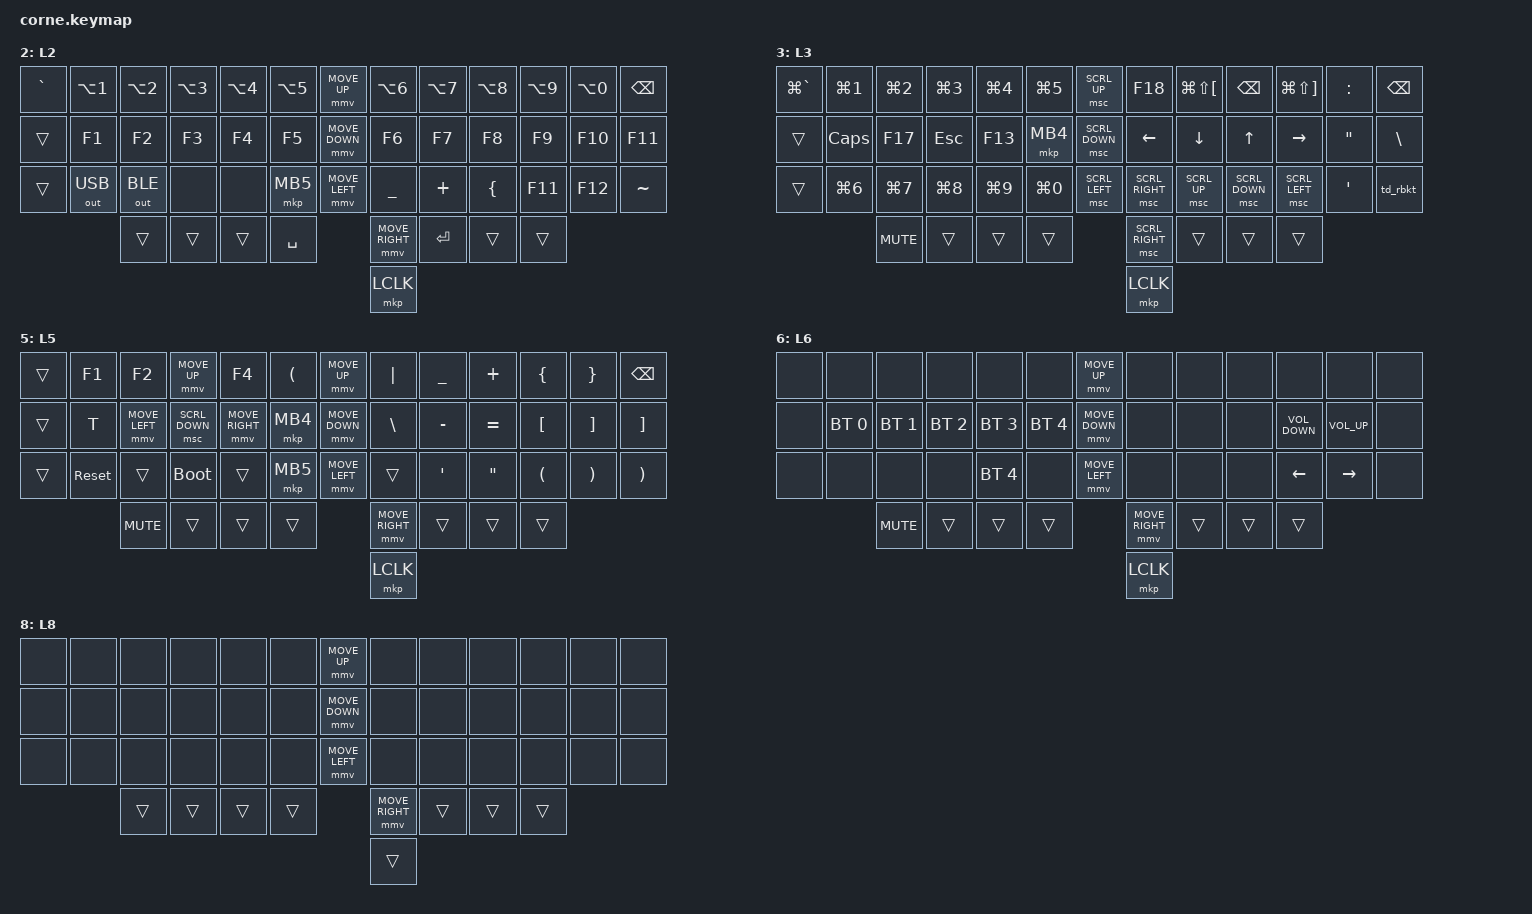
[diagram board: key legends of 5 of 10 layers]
#include <behaviors.dtsi>
#include <dt-bindings/zmk/bt.h>
#include <dt-bindings/zmk/keys.h>
#include <dt-bindings/zmk/mouse.h>
#include <dt-bindings/zmk/outputs.h>
#include <dt-bindings/zmk/rgb.h>

#define ZMK_MOUSE_DEFAULT_MOVE_VAL 1200  // 600
#define ZMK_MOUSE_DEFAULT_SCRL_VAL 20    // 10
#define U_MS_U &mmv MOVE_UP
#define U_MS_D &mmv MOVE_DOWN
#define U_MS_L &mmv MOVE_LEFT
#define U_MS_R &mmv MOVE_RIGHT



&msc {
    acceleration-exponent = <0>;      // 0
    time-to-max-speed-ms = <0>;       // 300
    delay-ms = <0>;                   // 0
};

/ {
    macros {
        cmd_shift_left: cmd_shift_left {
            compatible = "zmk,behavior-macro";
            #binding-cells = <0>;
            bindings
                = <&kp LGUI>
                , <&kp LSHFT>
                ;
        };
        cmd_shift_right: cmd_shift_right {
            compatible = "zmk,behavior-macro";
            #binding-cells = <0>;
            bindings
                = <&kp RGUI>
                , <&kp RSHFT>
                ;
        };
        pwd_macro: pwd_macro {
            compatible = "zmk,behavior-macro";
            #binding-cells = <0>;
            bindings
                = <&kp F &kp D &kp S &kp A &kp J &kp K &kp L &kp SEMI>
                ;
        };

        pwd_enter_macro: pwd_enter_macro {
            compatible = "zmk,behavior-macro";
            #binding-cells = <0>;
            bindings
                = <&kp F &kp D &kp S &kp A &kp J &kp K &kp L &kp SEMI>,
                  <&macro_wait_time 500>,
                  <&kp ENTER>
                ;
        };

        lock_macro: lock_macro {
            compatible = "zmk,behavior-macro";
            #binding-cells = <0>;
            bindings
                = <&kp LG(LC(Q)) &kp ESC>
                ;
        };

        ctrl_c: ctrl_c {
            compatible = "zmk,behavior-macro";
            #binding-cells = <0>;
            bindings = <&kp LG(C)>;
        };

        ctrl_v: ctrl_v {
            compatible = "zmk,behavior-macro";
            #binding-cells = <0>;
            bindings = <&kp LG(V)>;
        };
    };

    conditional_layers {
        compatible = "zmk,conditional-layers";
        tri_layer {
            if-layers = <3 4>;
            then-layer = <9>;
        }; 
    };

    behaviors {
        mo_sl: behavior_mo_tog {
            compatible = "zmk,behavior-hold-tap";
            #binding-cells = <2>;
            flavor = "hold-preferred";
            tapping-term-ms = <200>;
            bindings = <&mo>, <&sl>;
        };

        mo_sk: behavior_mo_sk {
            compatible = "zmk,behavior-hold-tap";
            #binding-cells = <2>;
            flavor = "hold-preferred";
            tapping-term-ms = <200>;
            bindings = <&mo>, <&sk>;
        };

        gresc: grave_escape {
            compatible = "zmk,behavior-mod-morph";
            #binding-cells = <0>;
            bindings = <&kp ESC>, <&kp GRAVE>;
            mods = <(MOD_LGUI|MOD_LSFT|MOD_RGUI|MOD_RSFT)>;
        };

        td0: td0 {
            compatible = "zmk,behavior-tap-dance";
            label = "TD0";
            #binding-cells = <0>;
            bindings = <&kp LEFT_SHIFT>, <&kp CAPS>;
        };

        tde: tap_dance_e {
            compatible = "zmk,behavior-tap-dance";
            #binding-cells = <0>;
            bindings = <&kp E>, <&kp LS(E)>;
        };

        td_minus: tap_dance_minus {
            compatible = "zmk,behavior-tap-dance";
            #binding-cells = <0>;
            bindings = <&kp MINUS>, <&kp UNDERSCORE>;
        };

        td_equal: tap_dance_equal {
            compatible = "zmk,behavior-tap-dance";
            #binding-cells = <0>;
            bindings = <&kp EQUAL>, <&kp PLUS>;
        };

        td_lbkt: tap_dance_lbkt {
            compatible = "zmk,behavior-tap-dance";
            #binding-cells = <0>;
            bindings = <&kp LBKT>, <&kp LBRC>;
        };

        td_rbkt: tap_dance_rbkt {
            compatible = "zmk,behavior-tap-dance";
            #binding-cells = <0>;
            bindings = <&kp RBKT>, <&kp RBRC>;
        };

        td_grave: tap_dance_grave {
            compatible = "zmk,behavior-tap-dance";
            #binding-cells = <0>;
            bindings = <&kp GRAVE>, <&kp TILDE>;
        };

        td_bslh: tap_dance_bslh {
            compatible = "zmk,behavior-tap-dance";
            #binding-cells = <0>;
            bindings = <&kp BSLH>, <&kp PIPE>;
        };

        td_sqt: tap_dance_sqt {
            compatible = "zmk,behavior-tap-dance";
            #binding-cells = <0>;
            bindings = <&kp SQT>, <&kp DQT>;
        };

        td_ctrl_c: tap_dance_ctrl_c {
            compatible = "zmk,behavior-tap-dance";
            #binding-cells = <0>;
            bindings = <&kp C>, <&kp LG(C)>;
        };

        td_ctrl_v: tap_dance_ctrl_v {
            compatible = "zmk,behavior-tap-dance";
            #binding-cells = <0>;
            bindings = <&kp V>, <&kp LG(V)>;
        };

        td_ctrl_x: tap_dance_ctrl_x {
            compatible = "zmk,behavior-tap-dance";
            #binding-cells = <0>;
            bindings = <&kp X>, <&kp LA(LG(V))>;
        };

        hm: homerow_mods {
            compatible = "zmk,behavior-hold-tap";
            label = "HOMEROW_MODS";
            bindings = <&kp>, <&kp>;

            #binding-cells = <2>;
            tapping-term-ms = <200>;
            quick-tap-ms = <180>;
            flavor = "tap-preferred";
        };

        as: auto_shift {
            compatible = "zmk,behavior-hold-tap";
            label = "AUTO_SHIFT";
            bindings = <&kp>, <&kp>;
            #binding-cells = <2>;
            tapping-term-ms = <135>;
            quick-tap-ms = <0>;
        };

        mmv {
            acceleration-exponent = <1>;      // 1
            time-to-max-speed-ms = <900>;    // 40
            delay-ms = <0>;                   // 0
        };

    };

    rgb_encoder: rgb_encoder {
        compatible = "zmk,behavior-sensor-rotate";
        label = "RGB_ENCODER";
        #sensor-binding-cells = <0>;
        bindings = <&rgb_ug RGB_BRI>, <&rgb_ug RGB_BRD>;
    };

    scroll_encoder: scroll_encoder {
        compatible = "zmk,behavior-sensor-rotate";
        #sensor-binding-cells = <0>;
        bindings = <&msc SCRL_DOWN>, <&msc SCRL_UP>;

        tap-ms = <30>;
    };

    combos {
        compatible = "zmk,combos";

        enter {
            bindings = <&kp ENTER>;
            key-positions = <21 22>;
        };

        tab_right {
            bindings = <&kp TAB>;
            key-positions = <8 9>;
            layers = <0>;
        };

        delete_combo {
            bindings = <&kp BSPC>;
            key-positions = <9 10>;
            layers = <0 1 5>;
        };

        tab_0_1 {
            bindings = <&kp TAB>;
            key-positions = <0 1>;
        };

        caps_switch {
            bindings = <&kp CAPS>;
            key-positions = <2 3>;
        };
        
        switch_app_back {
          bindings = <&kp LG(TAB)>;
          key-positions = <22 44>;
        };

        kitty_on_right {
            bindings = <&kp LG(SEMI)>;
            key-positions = <21 44>;
        };

        kitty_on_8_21 {
            bindings = <&kp LG(SEMI)>;
            key-positions = <8 21>;
        };

        input_switch {
            bindings = <&kp F18>;
            key-positions = <3 4>;
        };

        nvim_flash_d_k {
            bindings = <&kp LC(SEMI)>;
            key-positions = <16 22>;
        };

        lock_screen {
            bindings = <&lock_macro>;
            key-positions = <10 11>;
            layers = <3 6>;
        };

        input_pwd {
            bindings = <&pwd_macro>;
            key-positions = <23 24>;
            layers = <3 6>;
        };

        input_pwd_enter {
            bindings = <&pwd_enter_macro>;
            key-positions = <22 23 24>;
            layers = <3 6>;
        };

        bt_clear {
            bindings = <&bt BT_CLR>;
            key-positions = <1 2 3 4>;
            layers = <6>;
        };

    };

    keymap {
        compatible = "zmk,keymap";

        default_layer {
            display-name = "QWERTY";

            // --------------------------------------------------------------------------------
            // |  TAB |  Q  |  W  |  E  |  R  |  T  |                ↑    |  Y  |  U   |  I  |  O  |  P  | BKSP |      &kp UP_ARROW 
            // | SHIFT |  A  |  S  |  D  |  F  |  G  |               ↓    |  H  |  J   |  K  |  L  |  ;  |  '   | 
            // | CTRL |  Z  |  X  |  C  |  V  |  B  |                ←    |  N  |  M   |  ,  |  .  |  /  | ESC  |
            //                    | GUI | LWR | SPC |                →    | ENT | RSE  | ALT |
            //                                                      enter

            bindings = <
&kp TAB &kp Q  &kp W      &hm LA(LGUI) E     &hm LS(LGUI) R  &kp T          &kp UP_ARROW     &kp Y        &hm RS(RGUI) U  &hm RA(RGUI) I      &kp O    &kp P     &kp BSPC
&sl 6 &hm LEFT_SHIFT A  &hm LEFT_ALT S  &hm LEFT_CONTROL D     &hm LEFT_GUI F  &lt 6 G  &kp DOWN_ARROW   &hm RIGHT_SHIFT H        &hm LEFT_GUI J  &hm RIGHT_CONTROL K      &hm RIGHT_ALT L   &hm RIGHT_SHIFT SEMI  &sl 8
&kp LG(LS(LC(LALT)))       &hm LG(LS(LC(LALT))) Z  &hm LA(LG(V)) X       &hm LG(C) C     &hm LG(V) V  &kp B          &kp LEFT_ARROW   &kp N        &kp M  &kp COMMA  &kp DOT  &hm RG(RS(RC(RALT))) FSLH  &kp RG(RS(RC(RALT)))
                 &kp C_MUTE  &mo_sl 5 7  &lt 1 TAB  &mo_sk 3 LEFT_SHIFT    &kp RIGHT_ARROW  &lt 4 SPACE  &mo_sl 2 8 &lt 6 ENTER 
                                                             &kp ENTER
            >;

        };

        lower_layer {
            display-name = "L1";

            // -----------------------------------------------------------------------------------------
            // |  TAB |  1  |  2  |  3  |  4  |  5  |   |  6  |  7  |  8  |  9  |  0  | BKSP |
            // | BTCLR| BT1 | BT2 | BT3 | BT4 | BT5 |   | LFT | DWN |  UP | RGT |     |      |
            // | SHFT |     |     |     |     |     |   |     |     |     |     |     |      |
            //                    | GUI |     | SPC |   | ENT |     | ALT |

            bindings = <
&trans  &kp N1           &kp N2          &kp N3        &kp N4        &kp N5             &mmv MOVE_DOWN   &kp N6           &kp N7           &kp N8           &kp N9        &kp N0    &kp BSPC
&trans  &kp EXCL      &kp AT        &kp HASH   &kp DLLR   &kp PRCNT    &mmv MOVE_DOWN   &kp CARET  &kp AMPS   &kp ASTRK  &kp LPAR   &kp RPAR  &kp BSLH
&trans  &rgb_ug RGB_OFF  &rgb_ug RGB_ON  &rgb_ug RGB_COLOR_HSB(36,26,98)       &trans        &rgb_ug RGB_EFF    &mmv MOVE_LEFT   &rgb_ug RGB_EFR  &kp MINUS  &kp UNDER &kp EQUAL  &kp PLUS  &kp F12
                         &kp C_MUTE      &trans        &trans        &trans             &mmv MOVE_RIGHT  &kp INS          &kp DEL          &trans
                                                                                        &mkp LCLK
            >;

        };

        raise_layer {
            display-name = "L2";

            // -----------------------------------------------------------------------------------------
            // |  TAB |  !  |  @  |  #  |  $  |  %  |   |  ^  |  &  |  *  |  (  |  )  | BKSP |
            // | CTRL |     |     |     |     |     |   |  -  |  =  |  [  |  ]  |  \  |  `   |
            // | SHFT |     |     |     |     |     |   |  _  |  +  |  {  |  }  | "|" |  ~   |
            //                    | GUI |     | SPC |   | ENT |     | ALT |
            // &trans  &bt BT_CLR    &mkp LCLK     &mkp MCLK  &mkp RCLK  &mkp MB4     &mmv MOVE_DOWN   &kp MINUS  &kp EQUAL  &kp LBKT   &kp RBKT  &kp BSLH  &kp GRAVE

            bindings = <
&kp GRAVE  &kp LA(N1)    &kp LA(N2)  &kp LA(N3) &kp LA(N4)  &kp LA(N5)    &mmv MOVE_UP    &kp LA(N6)    &kp LA(N7)  &kp LA(N8) &kp LA(N9)  &kp LA(N0)   &kp BSPC
&trans  &kp F1      &kp F2      &kp F3       &kp F4     &kp F5      &mmv MOVE_DOWN     &kp F6       &kp F7     &kp F8       &kp F9      &kp F10       &kp F11
&trans  &out OUT_USB  &out OUT_BLE  &none      &none      &mkp MB5     &mmv MOVE_LEFT   &kp UNDER  &kp PLUS   &kp LBRC   &kp F11  &kp F12   &kp TILDE
                      &trans        &trans     &trans     &kp SPACE    &mmv MOVE_RIGHT  &kp RET    &trans     &trans
                                                                       &mkp LCLK
            >;

        };

        layer_3 {
            display-name = "L3";
            bindings = <
&kp LG(GRAVE)  &kp LG(N1)     &kp LG(N2)      &kp LG(N3)    &kp LG(N4)    &kp LG(N5)      &msc SCRL_UP      &kp F18       &kp LG(LS(LBKT))    &kp BSPC       &kp LG(LS(RBKT))    &kp COLON   &kp BSPC
&trans  &kp CAPS     &kp F17   &kp ESC      &kp F13  &mkp MB4    &msc SCRL_DOWN   &kp LEFT     &kp DOWN   &kp UP       &kp RIGHT   &kp DQT  &kp BSLH
&trans  &kp LG(N6)     &kp LG(N7)      &kp LG(N8)    &kp LG(N9)    &kp LG(N0)   &msc SCRL_LEFT  &msc SCRL_RIGHT &msc SCRL_UP &msc SCRL_DOWN &msc SCRL_LEFT  &kp SQT  &td_rbkt
                    &kp C_MUTE  &trans       &trans     &trans      &msc SCRL_RIGHT  &trans       &trans     &trans
                                                                    &mkp LCLK
            >;

        };

        layer_4 {
            display-name = "L4";
            bindings = <
&trans  &kp TILDE     &kp LG(LS(LC(LA(N9))))     &mmv MOVE_UP       &kp LG(LS(LC(LA(N0))))      &kp TILDE      &mmv MOVE_UP     &kp F6       &kp LBKT  &kp RBKT  &kp LBRC   &kp RBRC   &kp F11
&kp CAPS &kp GRAVE   &mmv MOVE_LEFT   &mmv MOVE_DOWN      &mmv MOVE_RIGHT  &kp GRAVE    &mmv MOVE_DOWN   &kp DQT  &mkp LCLK  &none   &mkp RCLK    &none  &none
&trans  &trans  &trans      &trans  &trans     &trans    &mmv MOVE_LEFT   &kp SQT       &kp DQT  &kp SQT &none  &none   &kp PAUSE_BREAK
                    &kp C_MUTE  &trans       &trans     &trans      &mmv MOVE_RIGHT  &trans       &trans     &trans
                                                                    &mkp LCLK
            >;

            sensor-bindings = <&inc_dec_kp C_BRI_INC C_BRI_DEC>;
        };

        layer_5 {
            display-name = "L5";
            bindings = <
&trans  &kp F1      &kp F2      &mmv MOVE_UP       &kp F4    &kp LPAR      &mmv MOVE_UP     &kp PIPE    &kp UNDER     &kp PLUS     &kp LBRC       &kp RBRC       &kp BSPC
&trans  &kp T      &mmv MOVE_LEFT   &msc SCRL_DOWN      &mmv MOVE_RIGHT  &mkp MB4    &mmv MOVE_DOWN  &kp BSLH  &kp MINUS    &kp EQUAL     &kp LBKT  &kp RBKT  &kp RBKT
&trans  &sys_reset  &trans      &bootloader  &trans     &mkp MB5    &mmv MOVE_LEFT   &trans       &kp SQT   &kp DQT  &kp LPAR   &kp RPAR   &kp RPAR
                    &kp C_MUTE  &trans       &trans     &trans      &mmv MOVE_RIGHT  &trans       &trans     &trans
                                                                    &mkp LCLK
            >;

            label = "L8";
        };

        layer_6 {
            display-name = "L6";
            bindings = <
&none   &none     &none     &none      &none   &none    &mmv MOVE_UP     &none   &none     &none     &none      &none   &none
&none   &bt BT_SEL 0    &bt BT_SEL 1  &bt BT_SEL 2  &bt BT_SEL 3    &bt BT_SEL 4   &mmv MOVE_DOWN   &none   &none     &none     &kp C_VOLUME_DOWN   &kp C_VOLUME_UP  &none
&none   &none     &none     &none     &bt BT_SEL 4  &none    &mmv MOVE_LEFT   &none   &none     &none     &kp LEFT  &kp RIGHT   &none
                    &kp C_MUTE  &trans       &trans     &trans      &mmv MOVE_RIGHT  &trans       &trans     &trans
                                                                    &mkp LCLK
            >;

        };

        layer_7 {
            display-name = "L7";
            bindings = <
&none   &none     &none     &none      &none   &none    &mmv MOVE_UP     &none   &none     &none     &none      &none   &none
&trans  &kp T      &mmv MOVE_LEFT   &msc SCRL_DOWN      &sk LG(LS(LA(LCTRL)))  &mkp MB4    &mmv MOVE_DOWN   &none   &sk LS(LALT)   &none     &none      &none   &none
&none   &none     &none     &none      &none   &none    &mmv MOVE_LEFT   &none   &none     &none     &none      &none   &none
                   &trans  &trans       &trans     &trans      &mmv MOVE_RIGHT  &trans       &trans     &trans
                                                                    &trans
            >;

        };

        layer_8 {
            display-name = "L8";
            bindings = <
&none   &none     &none     &none      &none   &none    &mmv MOVE_UP     &none   &none     &none     &none      &none   &none
&none   &none     &none     &none      &none   &none    &mmv MOVE_DOWN   &none   &none     &none     &none      &none   &none
&none   &none     &none     &none      &none   &none    &mmv MOVE_LEFT   &none   &none     &none     &none      &none   &none
                   &trans  &trans       &trans     &trans      &mmv MOVE_RIGHT  &trans       &trans     &trans
                                                                    &trans
            >;
        };

        layer_9 {
            display-name = "L9";
            bindings = <
&none   &none     &kp LS(LALT)  &kp C_BRI_DEC &kp C_BRI_INC  &none    &mmv MOVE_UP   &kp C_MUTE  &kp C_VOLUME_DOWN &kp C_VOLUME_UP  &kp RS(RALT)  &none &none
&none   &none     &none     &none      &none   &none    &mmv MOVE_DOWN   &msc SCRL_RIGHT &msc SCRL_UP &msc SCRL_DOWN &msc SCRL_LEFT &none
&none   &none     &none     &none      &none   &none    &mmv MOVE_LEFT   &none   &none     &none     &none   &none   &none
                   &trans  &trans       &trans     &trans      &mmv MOVE_RIGHT  &trans       &trans     &trans
                                                                    &trans
            >;
        };
    };
};
